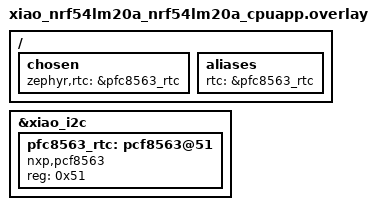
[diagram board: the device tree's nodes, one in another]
/ {
	chosen {
		zephyr,rtc = &pfc8563_rtc;
	};

	aliases {
		rtc = &pfc8563_rtc;
	};
};

&xiao_i2c {
	status = "okay";

	pfc8563_rtc: pcf8563@51 {
		compatible = "nxp,pcf8563";
		reg = <0x51>;
		status = "okay";
	};
};
